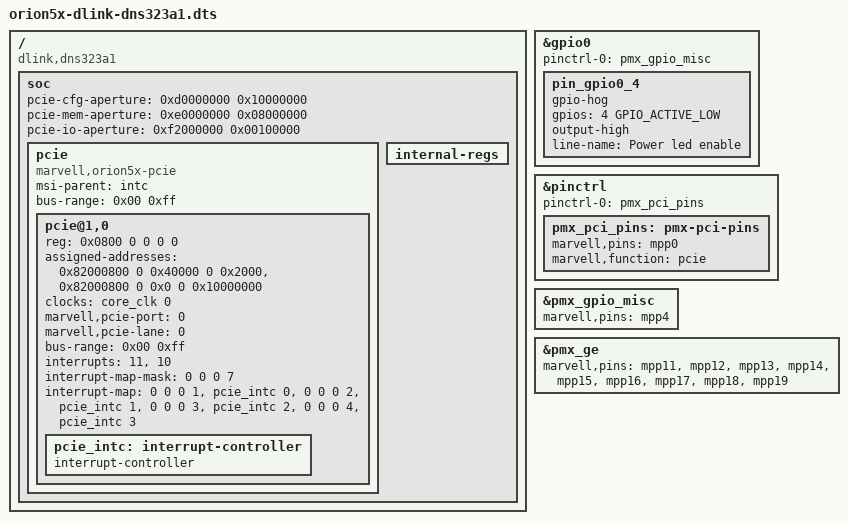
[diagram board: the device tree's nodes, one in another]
// SPDX-License-Identifier: GPL-2.0-only
/*
 * Copyright (C) 2022 Mauri Sandberg <maukka@ext.kapsi.fi>
 *
 */

/dts-v1/;

#include <dt-bindings/gpio/gpio.h>
#include <dt-bindings/input/input.h>
#include <dt-bindings/leds/common.h>
#include <dt-bindings/interrupt-controller/irq.h>
#include "orion5x-mv88f5181.dtsi"
#include "orion5x-dlink-dns323.dtsi"

/ {
	compatible = "dlink,dns323a1", "dlink,dns323", "marvell,orion5x-88f5181",
		     "marvell,orion5x";

	/delete-node/ sa-sram;	/* crypto_sram */

	soc {
		pcie-cfg-aperture = <0xd0000000 0x10000000>; /* 256 MiB config space */
		pcie-mem-aperture = <0xe0000000 0x08000000>; /* 128 MiB memory space */
		pcie-io-aperture  = <0xf2000000 0x00100000>; /*   1 MiB I/O space */

		pcie {
			compatible = "marvell,orion5x-pcie";
			status = "okay";
			device_type = "pci";
			#address-cells = <3>;
			#size-cells = <2>;

			msi-parent = <&intc>;
			bus-range = <0x00 0xff>;

			ranges = <0x82000000 0   0x40000    MBUS_ID(0xf0, 0x01) 0x40000 0 0x2000     /* Port 0.0 Internal registers */
				  0x82000000 0   0x0        MBUS_ID(0x04, 0x79) 0       0 0x10000000 /* Port 0.0 Config space */
				  0x82000000 0x1 0x0        MBUS_ID(0x04, 0x59) 0       1 0          /* Port 0.0 Mem */
				  0x81000000 0x1 0x0        MBUS_ID(0x04, 0x51) 0       1 0>;        /* Port 0.0 I/O */

			pcie@1,0 {
				status = "okay";
				reg = <0x0800 0 0 0 0>;  /* BDF 0:1.0 */

				device_type = "pci";
				assigned-addresses = <0x82000800 0 0x40000 0 0x2000>,
						     <0x82000800 0 0x0     0 0x10000000>;
				clocks = <&core_clk 0>;
				marvell,pcie-port = <0>;
				marvell,pcie-lane = <0>;

				#address-cells = <3>;
				#size-cells = <2>;
				#interrupt-cells = <1>;
				ranges = <0x82000000 0 0 0x82000000 0x1 0 1 0
				          0x81000000 0 0 0x81000000 0x1 0 1 0>;
				bus-range = <0x00 0xff>;

				interrupt-names = "intx", "error";
				interrupts = <11>, <10>;
				interrupt-map-mask = <0 0 0 7>;
				interrupt-map = <0 0 0 1 &pcie_intc 0>,
				<0 0 0 2 &pcie_intc 1>,
				<0 0 0 3 &pcie_intc 2>,
				<0 0 0 4 &pcie_intc 3>;

				pcie_intc: interrupt-controller {
					interrupt-controller;
					#interrupt-cells = <1>;
				};
			};
		};

		internal-regs {
			/delete-node/ crypto@90000;
			/delete-node/ sata@80000;
		};
	};
};

&gpio0 {
	pinctrl-0 = <&pmx_gpio_misc>;
	pinctrl-names = "default";

	/* The DNS323 rev A1 power LED requires GPIO 4 to be low. */
	pin_gpio0_4 {
		gpio-hog;
		gpios = <4 GPIO_ACTIVE_LOW>;
		output-high;
		line-name = "Power led enable";
	};
};

&pinctrl {
	pinctrl-0 = <&pmx_pci_pins>;
	pinctrl-names = "default";

	pmx_pci_pins: pmx-pci-pins {
		marvell,pins = "mpp0";
		marvell,function = "pcie";
	};
};

&pmx_gpio_misc {
	marvell,pins = "mpp4";
};

&pmx_ge {
	marvell,pins = "mpp11", "mpp12", "mpp13", "mpp14", "mpp15",
		       "mpp16", "mpp17", "mpp18", "mpp19";
};
